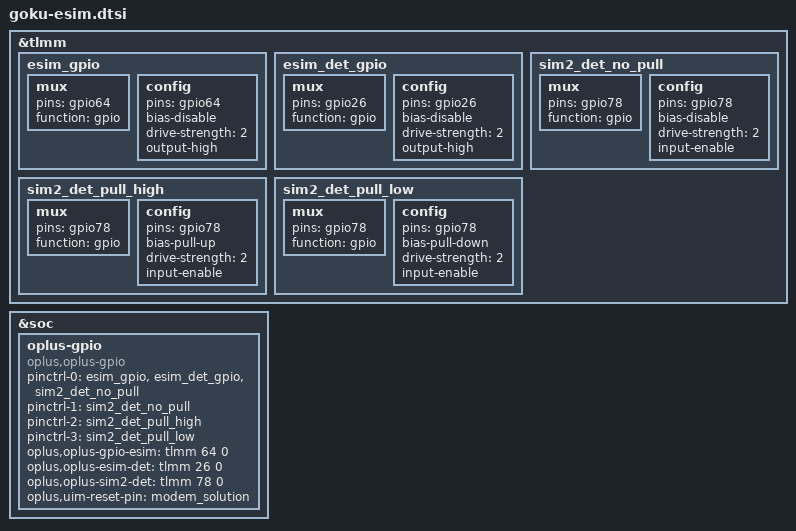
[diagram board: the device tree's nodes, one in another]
// SPDX-License-Identifier: GPL-2.0-only
/*
* Copyright (C) 2018-2020 Oplus. All rights reserved.
*/

&tlmm {
	//#ifdef OPLUS_FEATRUE_ESIM
	esim_gpio: esim_gpio {
		mux {
			pins = "gpio64";
			function = "gpio";
		};
		config {
			pins = "gpio64";
			bias-disable; /* NO pull */
			drive-strength = <2>; /* 2 MA */
			output-high;
		};
	};

	esim_det_gpio: esim_det_gpio {
		mux {
			pins = "gpio26";
			function = "gpio";
		};
		config {
			pins = "gpio26";
			bias-disable; /* NO pull */
			drive-strength = <2>; /* 2 MA */
			output-high;
		};
	};

	sim2_det_no_pull: sim2_det_no_pull {
		mux {
			pins = "gpio78";
			function = "gpio";
		};
		config {
			pins = "gpio78";
			bias-disable; /* NO pull */
			drive-strength = <2>; /* 2 MA */
			input-enable;
		};
	};

	sim2_det_pull_high: sim2_det_pull_high {
		mux {
			pins = "gpio78";
			function = "gpio";
		};
		config {
			pins = "gpio78";
			bias-pull-up; /* pull up */
			drive-strength = <2>; /* 2 MA */
			input-enable;
		};
	};

	sim2_det_pull_low: sim2_det_pull_low {
		mux {
			pins = "gpio78";
			function = "gpio";
		};
		config {
			pins = "gpio78";
			bias-pull-down; /* pull down */
			drive-strength = <2>; /* 2 MA */
			input-enable;
		};
	};
	//#endif /* OPLUS_FEATRUE_ESIM */
};
&soc {
	//#ifdef OPLUS_FEATRUE_ESIM
	oplus-gpio {
		compatible = "oplus,oplus-gpio";
		pinctrl-names = "default", "sim2_det_no_pull", "sim2_det_pull_high", "sim2_det_pull_low";
		pinctrl-0 = <&esim_gpio &esim_det_gpio &sim2_det_no_pull>;
		pinctrl-1 = <&sim2_det_no_pull>;
		pinctrl-2 = <&sim2_det_pull_high>;
		pinctrl-3 = <&sim2_det_pull_low>;
		oplus,oplus-gpio-esim = <&tlmm 64 0>;
		oplus,oplus-esim-det = <&tlmm 26 0>;
		oplus,oplus-sim2-det = <&tlmm 78 0>;
                oplus,uim-reset-pin = "modem_solution";
	};
	//#endif /* OPLUS_FEATRUE_ESIM */
};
